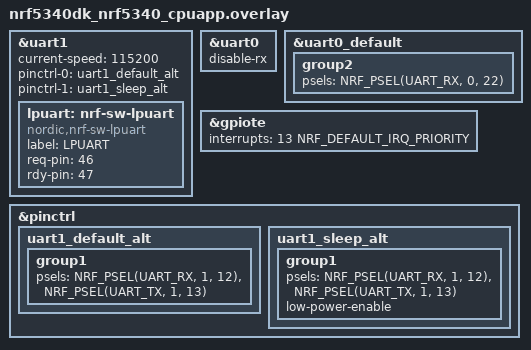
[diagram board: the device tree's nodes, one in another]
/* SPDX-License-Identifier: LicenseRef-Nordic-5-Clause */

&uart1 {
	status = "okay";
	current-speed = <115200>;

	pinctrl-0 = <&uart1_default_alt>;
	pinctrl-1 = <&uart1_sleep_alt>;
	pinctrl-names = "default", "sleep";
	lpuart: nrf-sw-lpuart {
		compatible = "nordic,nrf-sw-lpuart";
		status = "okay";
		label = "LPUART";
		req-pin = <46>;
		rdy-pin = <47>;
	};
};

&uart0 {
	disable-rx;
};

&uart0_default {
	group2 {
		/* Remove assignment of P0.21 as CTS. This is a temporary
		 * workaround for increased current consumption observed
		 * on nRF5340 DKs only (~200 uA more on v0.9.0 and ~400 uA
		 * more on v2.0.0). */
		psels = <NRF_PSEL(UART_RX, 0, 22)>;
	};
};

&gpiote {
	interrupts = <13 NRF_DEFAULT_IRQ_PRIORITY>;
};

&pinctrl {
	uart1_default_alt: uart1_default_alt {
		group1 {
			psels = <NRF_PSEL(UART_RX, 1, 12)>,
				<NRF_PSEL(UART_TX, 1, 13)>;
		};
	};

	uart1_sleep_alt: uart1_sleep_alt {
		group1 {
			psels = <NRF_PSEL(UART_RX, 1, 12)>,
				<NRF_PSEL(UART_TX, 1, 13)>;
			low-power-enable;
		};
	};
};
